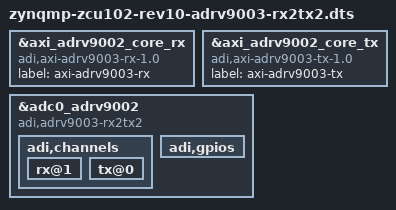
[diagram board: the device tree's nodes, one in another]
// SPDX-License-Identifier: GPL-2.0
/*
 * Analog Devices ADRV9002
 *
 * hdl_project: <adrv9001/zcu102>
 * board_revision: <>
 *
 * Copyright (C) 2022 Analog Devices Inc.
 */

#include "zynqmp-zcu102-rev10-adrv9002-rx2tx2.dts"

&axi_adrv9002_core_rx {
	compatible = "adi,axi-adrv9003-rx-1.0";
	label = "axi-adrv9003-rx";
};

&axi_adrv9002_core_tx {
	/* just have TX1 */
	compatible = "adi,axi-adrv9003-tx-1.0";
	label = "axi-adrv9003-tx";
};

&adc0_adrv9002 {
	compatible = "adi,adrv9003-rx2tx2";

	/* delete tx2 and ORX2 gpio */
	adi,channels {
		/delete-node/ tx@1;
		rx@1 {
			/delete-property/ orx-gpios;
		};

		tx@0 {
			/delete-property/ adi,dpd;
		};
	};

	adi,gpios {
		/delete-node/ gpio@1;
	};
};
